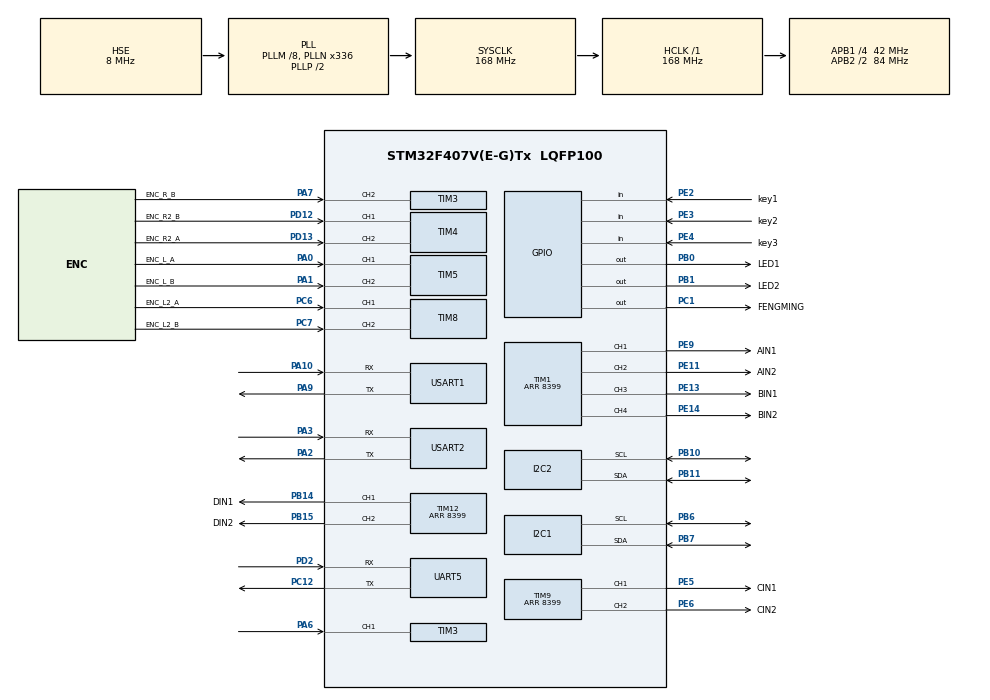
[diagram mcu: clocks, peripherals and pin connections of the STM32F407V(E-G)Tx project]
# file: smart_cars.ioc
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Dma.Request0=USART1_RX
Dma.USART1_RX.0.Direction=DMA_PERIPH_TO_MEMORY
Dma.USART1_RX.0.FIFOMode=DMA_FIFOMODE_DISABLE
Dma.USART1_RX.0.Instance=DMA2_Stream2
Dma.USART1_RX.0.MemDataAlignment=DMA_MDATAALIGN_BYTE
Dma.USART1_RX.0.MemInc=DMA_MINC_ENABLE
Dma.USART1_RX.0.Mode=DMA_CIRCULAR
Dma.USART1_RX.0.PeriphDataAlignment=DMA_PDATAALIGN_BYTE
Dma.USART1_RX.0.PeriphInc=DMA_PINC_DISABLE
Dma.USART1_RX.0.Priority=DMA_PRIORITY_HIGH
Mcu.Family=STM32F4
Mcu.Name=STM32F407V(E-G)Tx
Mcu.Package=LQFP100
NVIC.DMA2_Stream2_IRQn=true\:0\:0\:false\:false\:true\:false\:true\:true
NVIC.PriorityGroup=NVIC_PRIORITYGROUP_4
NVIC.TIM6_DAC_IRQn=true\:0\:0\:false\:false\:true\:true\:true\:true
NVIC.TIM7_IRQn=true\:0\:0\:false\:false\:true\:true\:true\:true
NVIC.USART1_IRQn=true\:0\:0\:false\:false\:true\:true\:true\:true
PA0-WKUP.GPIO_Label=ENC_L_A
PA0-WKUP.Signal=S_TIM5_CH1
PA1.GPIO_Label=ENC_L_B
PA1.Signal=S_TIM5_CH2
PA10.Mode=Asynchronous
PA10.Signal=USART1_RX
PA2.Mode=Asynchronous
PA2.Signal=USART2_TX
PA3.Mode=Asynchronous
PA3.Signal=USART2_RX
PA6.Signal=S_TIM3_CH1
PA7.GPIO_Label=ENC_R_B
PA7.Signal=S_TIM3_CH2
PA9.Mode=Asynchronous
PA9.Signal=USART1_TX
PB0.GPIO_Label=LED1
PB0.Signal=GPIO_Output
PB1.GPIO_Label=LED2
PB1.Signal=GPIO_Output
PB10.Mode=I2C
PB10.Signal=I2C2_SCL
PB11.Mode=I2C
PB11.Signal=I2C2_SDA
PB14.GPIO_Label=DIN1
PB14.Signal=S_TIM12_CH1
PB15.GPIO_Label=DIN2
PB15.Signal=S_TIM12_CH2
PB6.Mode=I2C
PB6.Signal=I2C1_SCL
PB7.Mode=I2C
PB7.Signal=I2C1_SDA
PC1.GPIO_Label=FENGMING
PC1.Signal=GPIO_Output
PC12.Mode=Asynchronous
PC12.Signal=UART5_TX
PC14-OSC32_IN.Mode=LSE-External-Oscillator
PC14-OSC32_IN.Signal=RCC_OSC32_IN
PC15-OSC32_OUT.Mode=LSE-External-Oscillator
PC15-OSC32_OUT.Signal=RCC_OSC32_OUT
PC6.GPIO_Label=ENC_L2_A
PC6.Signal=S_TIM8_CH1
PC7.GPIO_Label=ENC_L2_B
PC7.Signal=S_TIM8_CH2
PD12.GPIO_Label=ENC_R2_B
PD12.Signal=S_TIM4_CH1
PD13.GPIO_Label=ENC_R2_A
PD13.Signal=S_TIM4_CH2
PD2.Mode=Asynchronous
PD2.Signal=UART5_RX
PE11.GPIO_Label=AIN2
PE11.Signal=S_TIM1_CH2
PE13.GPIO_Label=BIN1
PE13.Signal=S_TIM1_CH3
PE14.GPIO_Label=BIN2
PE14.Signal=S_TIM1_CH4
PE2.GPIO_Label=key1
PE2.Signal=GPIO_Input
PE3.GPIO_Label=key2
PE3.Signal=GPIO_Input
PE4.GPIO_Label=key3
PE4.Signal=GPIO_Input
PE5.GPIO_Label=CIN1
PE5.Signal=S_TIM9_CH1
PE6.GPIO_Label=CIN2
PE6.Signal=S_TIM9_CH2
PE9.GPIO_Label=AIN1
PE9.Signal=S_TIM1_CH1
PH0-OSC_IN.Mode=HSE-External-Oscillator
PH0-OSC_IN.Signal=RCC_OSC_IN
PH1-OSC_OUT.Mode=HSE-External-Oscillator
PH1-OSC_OUT.Signal=RCC_OSC_OUT
ProjectManager.HeapSize=0x200
ProjectManager.StackSize=0x400
ProjectManager.TargetToolchain=MDK-ARM V5.32
RCC.48MHZClocksFreq_Value=84000000
RCC.AHBFreq_Value=168000000
RCC.APB1CLKDivider=RCC_HCLK_DIV4
RCC.APB1Freq_Value=42000000
RCC.APB1TimFreq_Value=84000000
RCC.APB2CLKDivider=RCC_HCLK_DIV2
RCC.APB2Freq_Value=84000000
RCC.APB2TimFreq_Value=168000000
RCC.CortexFreq_Value=168000000
RCC.HCLKFreq_Value=168000000
RCC.HSE_VALUE=8000000
RCC.HSI_VALUE=16000000
RCC.PLLM=8
RCC.PLLN=336
RCC.PLLSourceVirtual=RCC_PLLSOURCE_HSE
RCC.SYSCLKFreq_VALUE=168000000
RCC.SYSCLKSource=RCC_SYSCLKSOURCE_PLLCLK
RCC.VCOOutputFreq_Value=336000000
SH.S_TIM12_CH1.0=TIM12_CH1,PWM Generation1 CH1
SH.S_TIM12_CH2.0=TIM12_CH2,PWM Generation2 CH2
SH.S_TIM1_CH1.0=TIM1_CH1,PWM Generation1 CH1
SH.S_TIM1_CH2.0=TIM1_CH2,PWM Generation2 CH2
SH.S_TIM1_CH3.0=TIM1_CH3,PWM Generation3 CH3
SH.S_TIM1_CH4.0=TIM1_CH4,PWM Generation4 CH4
SH.S_TIM3_CH1.0=TIM3_CH1,Encoder_Interface
SH.S_TIM3_CH2.0=TIM3_CH2,Encoder_Interface
SH.S_TIM4_CH1.0=TIM4_CH1,Encoder_Interface
SH.S_TIM4_CH2.0=TIM4_CH2,Encoder_Interface
SH.S_TIM5_CH1.0=TIM5_CH1,Encoder_Interface
SH.S_TIM5_CH2.0=TIM5_CH2,Encoder_Interface
SH.S_TIM8_CH1.0=TIM8_CH1,Encoder_Interface
SH.S_TIM8_CH2.0=TIM8_CH2,Encoder_Interface
SH.S_TIM9_CH1.0=TIM9_CH1,PWM Generation1 CH1
SH.S_TIM9_CH2.0=TIM9_CH2,PWM Generation2 CH2
TIM1.AutoReloadPreload=TIM_AUTORELOAD_PRELOAD_ENABLE
TIM1.Channel-PWM\ Generation1\ CH1=TIM_CHANNEL_1
TIM1.Channel-PWM\ Generation2\ CH2=TIM_CHANNEL_2
TIM1.Channel-PWM\ Generation3\ CH3=TIM_CHANNEL_3
TIM1.Channel-PWM\ Generation4\ CH4=TIM_CHANNEL_4
TIM1.Period=8399
TIM12.AutoReloadPreload=TIM_AUTORELOAD_PRELOAD_ENABLE
TIM12.Channel-PWM\ Generation1\ CH1=TIM_CHANNEL_1
TIM12.Channel-PWM\ Generation2\ CH2=TIM_CHANNEL_2
TIM12.Period=8399
TIM3.EncoderMode=TIM_ENCODERMODE_TI12
TIM4.EncoderMode=TIM_ENCODERMODE_TI12
TIM5.EncoderMode=TIM_ENCODERMODE_TI12
TIM6.Period=9
TIM6.Prescaler=8933
TIM7.Period=9999
TIM7.Prescaler=83
TIM8.EncoderMode=TIM_ENCODERMODE_TI12
TIM9.AutoReloadPreload=TIM_AUTORELOAD_PRELOAD_ENABLE
TIM9.Channel-PWM\ Generation1\ CH1=TIM_CHANNEL_1
TIM9.Channel-PWM\ Generation2\ CH2=TIM_CHANNEL_2
TIM9.Period=8399
UART5.VirtualMode=Asynchronous
USART1.VirtualMode=VM_ASYNC
USART2.VirtualMode=VM_ASYNC
VP_TIM12_VS_ClockSourceINT.Mode=Internal
VP_TIM1_VS_ClockSourceINT.Mode=Internal
VP_TIM6_VS_ClockSourceINT.Mode=Enable_Timer
VP_TIM7_VS_ClockSourceINT.Mode=Enable_Timer
VP_TIM9_VS_ClockSourceINT.Mode=Internal
board=custom

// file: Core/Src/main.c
/* USER CODE BEGIN Header */
/**
  ******************************************************************************
  * @file           : main.c
  * @brief          : Main program body
  ******************************************************************************
  * @attention
  *
  * Copyright (c) 2026 STMicroelectronics.
  * All rights reserved.
  *
  * This software is licensed under terms that can be found in the LICENSE file
  * in the root directory of this software component.
  * If no LICENSE file comes with this software, it is provided AS-IS.
  *
  ******************************************************************************
  */
/* USER CODE END Header */
#include "main.h"
#include "dma.h"
#include "i2c.h"
#include "tim.h"
#include "usart.h"
#include "gpio.h"

/* USER CODE BEGIN Includes */
#include "task.h"
#include "imu.h"
#include "motor.h"
#include <stdint.h>

/* USER CODE END Includes */

/* USER CODE BEGIN PTD */
all_task_state_t current_task_state=SELECT_TASK;//创建全局变量，表示当前任务状态
/* USER CODE END PTD */

void SystemClock_Config(void);

int main(void)
{

  /* MCU Configuration--------------------------------------------------------*/

  /* Reset of all peripherals, Initializes the Flash interface and the Systick. */
  HAL_Init();

  /* Configure the system clock */
  SystemClock_Config();

  /* Initialize all configured peripherals */
  MX_GPIO_Init();
  MX_DMA_Init();
  MX_TIM3_Init();
  MX_TIM4_Init();
  MX_TIM5_Init();
  MX_USART2_UART_Init();
  MX_TIM1_Init();
  MX_TIM8_Init();
  MX_TIM9_Init();
  MX_TIM12_Init();
  MX_I2C1_Init();
  MX_I2C2_Init();
  MX_UART5_Init();
  MX_USART1_UART_Init();
  MX_TIM6_Init();
  MX_TIM7_Init();
  /* USER CODE BEGIN 2 */
  if (Task_Init() != HAL_OK)
  {
    Error_Handler();
  }
  /* USER CODE END 2 */

  if (Task_ReverseParking() != TASK_PARKING_SUCCESS)
  {
    Error_Handler();
  }

  /* USER CODE BEGIN WHILE */
  while (1)
  {
    IMU_Update();
    /* USER CODE END WHILE */
  }
  /* USER CODE END 3 */
}

void SystemClock_Config(void)
{
  RCC_OscInitTypeDef RCC_OscInitStruct = {0};
  RCC_ClkInitTypeDef RCC_ClkInitStruct = {0};

  /** Configure the main internal regulator output voltage
  */
  __HAL_RCC_PWR_CLK_ENABLE();
  __HAL_PWR_VOLTAGESCALING_CONFIG(PWR_REGULATOR_VOLTAGE_SCALE1);

  /** Initializes the RCC Oscillators according to the specified parameters
  * in the RCC_OscInitTypeDef structure.
  */
  RCC_OscInitStruct.OscillatorType = RCC_OSCILLATORTYPE_HSE;
  RCC_OscInitStruct.HSEState = RCC_HSE_ON;
  RCC_OscInitStruct.PLL.PLLState = RCC_PLL_ON;
  RCC_OscInitStruct.PLL.PLLSource = RCC_PLLSOURCE_HSE;
  RCC_OscInitStruct.PLL.PLLM = 8;
  RCC_OscInitStruct.PLL.PLLN = 336;
  RCC_OscInitStruct.PLL.PLLP = RCC_PLLP_DIV2;
  RCC_OscInitStruct.PLL.PLLQ = 4;
  if (HAL_RCC_OscConfig(&RCC_OscInitStruct) != HAL_OK)
  {
    Error_Handler();
  }

  /** Initializes the CPU, AHB and APB buses clocks
  */
  RCC_ClkInitStruct.ClockType = RCC_CLOCKTYPE_HCLK|RCC_CLOCKTYPE_SYSCLK
                              |RCC_CLOCKTYPE_PCLK1|RCC_CLOCKTYPE_PCLK2;
  RCC_ClkInitStruct.SYSCLKSource = RCC_SYSCLKSOURCE_PLLCLK;
  RCC_ClkInitStruct.AHBCLKDivider = RCC_SYSCLK_DIV1;
  RCC_ClkInitStruct.APB1CLKDivider = RCC_HCLK_DIV4;
  RCC_ClkInitStruct.APB2CLKDivider = RCC_HCLK_DIV2;

  if (HAL_RCC_ClockConfig(&RCC_ClkInitStruct, FLASH_LATENCY_5) != HAL_OK)
  {
    Error_Handler();
  }
}

void Error_Handler(void)
{
  __disable_irq();
  while (1)
  {
  }
}
